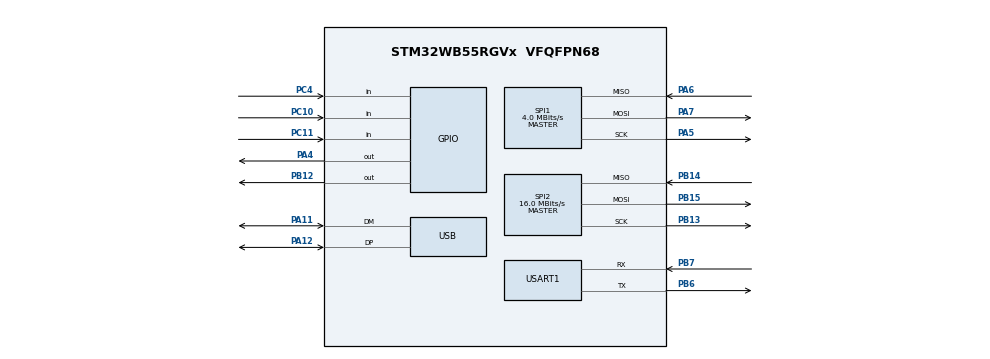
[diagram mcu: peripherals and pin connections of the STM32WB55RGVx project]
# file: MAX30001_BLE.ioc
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Dma.Request0=SPI1_RX
Dma.Request1=SPI1_TX
Dma.SPI1_RX.0.Direction=DMA_PERIPH_TO_MEMORY
Dma.SPI1_RX.0.EventEnable=DISABLE
Dma.SPI1_RX.0.Instance=DMA1_Channel1
Dma.SPI1_RX.0.MemDataAlignment=DMA_MDATAALIGN_BYTE
Dma.SPI1_RX.0.MemInc=DMA_MINC_ENABLE
Dma.SPI1_RX.0.Mode=DMA_NORMAL
Dma.SPI1_RX.0.PeriphDataAlignment=DMA_PDATAALIGN_BYTE
Dma.SPI1_RX.0.PeriphInc=DMA_PINC_DISABLE
Dma.SPI1_RX.0.Polarity=HAL_DMAMUX_REQ_GEN_RISING
Dma.SPI1_RX.0.Priority=DMA_PRIORITY_LOW
Dma.SPI1_RX.0.RequestNumber=1
Dma.SPI1_RX.0.SignalID=NONE
Dma.SPI1_RX.0.SyncEnable=DISABLE
Dma.SPI1_RX.0.SyncPolarity=HAL_DMAMUX_SYNC_NO_EVENT
Dma.SPI1_RX.0.SyncRequestNumber=1
Dma.SPI1_RX.0.SyncSignalID=NONE
Dma.SPI1_TX.1.Direction=DMA_MEMORY_TO_PERIPH
Dma.SPI1_TX.1.EventEnable=DISABLE
Dma.SPI1_TX.1.Instance=DMA1_Channel2
Dma.SPI1_TX.1.MemDataAlignment=DMA_MDATAALIGN_BYTE
Dma.SPI1_TX.1.MemInc=DMA_MINC_ENABLE
Dma.SPI1_TX.1.Mode=DMA_NORMAL
Dma.SPI1_TX.1.PeriphDataAlignment=DMA_PDATAALIGN_BYTE
Dma.SPI1_TX.1.PeriphInc=DMA_PINC_DISABLE
Dma.SPI1_TX.1.Polarity=HAL_DMAMUX_REQ_GEN_RISING
Dma.SPI1_TX.1.Priority=DMA_PRIORITY_LOW
Dma.SPI1_TX.1.RequestNumber=1
Dma.SPI1_TX.1.SignalID=NONE
Dma.SPI1_TX.1.SyncEnable=DISABLE
Dma.SPI1_TX.1.SyncPolarity=HAL_DMAMUX_SYNC_NO_EVENT
Dma.SPI1_TX.1.SyncRequestNumber=1
Dma.SPI1_TX.1.SyncSignalID=NONE
Mcu.Family=STM32WB
Mcu.Name=STM32WB55RGVx
Mcu.Package=VFQFPN68
NVIC.DMA1_Channel1_IRQn=true\:0\:0\:false\:false\:true\:false\:true
NVIC.DMA1_Channel2_IRQn=true\:0\:0\:false\:false\:true\:false\:true
NVIC.PriorityGroup=NVIC_PRIORITYGROUP_4
NVIC.USART1_IRQn=true\:0\:0\:false\:false\:true\:true\:true
NVIC.USB_LP_IRQn=true\:0\:0\:false\:false\:true\:true\:true
OSC_IN.Mode=HSE-External-Oscillator
OSC_IN.Signal=RCC_OSC_IN
OSC_OUT.Mode=HSE-External-Oscillator
OSC_OUT.Signal=RCC_OSC_OUT
PA11.Mode=Device
PA11.Signal=USB_DM
PA12.Mode=Device
PA12.Signal=USB_DP
PA13.Mode=Serial_Wire
PA13.Signal=SYS_JTMS-SWDIO
PA14.Mode=Serial_Wire
PA14.Signal=SYS_JTCK-SWCLK
PA4.GPIO_PuPd=GPIO_NOPULL
PA4.Signal=GPIO_Output
PA5.Mode=Full_Duplex_Master
PA5.Signal=SPI1_SCK
PA6.Mode=Full_Duplex_Master
PA6.Signal=SPI1_MISO
PA7.Mode=Full_Duplex_Master
PA7.Signal=SPI1_MOSI
PB12.GPIO_PuPd=GPIO_NOPULL
PB12.Signal=GPIO_Output
PB13.Mode=Full_Duplex_Master
PB13.Signal=SPI2_SCK
PB14.Mode=Full_Duplex_Master
PB14.Signal=SPI2_MISO
PB15.Mode=Full_Duplex_Master
PB15.Signal=SPI2_MOSI
PB6.GPIO_Speed=GPIO_SPEED_FREQ_VERY_HIGH
PB6.Mode=Asynchronous
PB6.Signal=USART1_TX
PB7.GPIO_PuPd=GPIO_PULLDOWN
PB7.GPIO_Speed=GPIO_SPEED_FREQ_VERY_HIGH
PB7.Mode=Asynchronous
PB7.Signal=USART1_RX
PC10.Signal=GPIO_Input
PC11.Signal=GPIO_Input
PC14-OSC32_IN.Mode=LSE-External-Oscillator
PC14-OSC32_IN.Signal=RCC_OSC32_IN
PC15-OSC32_OUT.Mode=LSE-External-Oscillator
PC15-OSC32_OUT.Signal=RCC_OSC32_OUT
PC4.Signal=GPIO_Input
ProjectManager.HeapSize=0x200
ProjectManager.StackSize=0x400
ProjectManager.TargetToolchain=STM32CubeIDE
RCC.ADCFreq_Value=128000000
RCC.AHBFreq_Value=32000000
RCC.APB1Freq_Value=32000000
RCC.APB1TimFreq_Value=32000000
RCC.APB2Freq_Value=32000000
RCC.APB2TimFreq_Value=32000000
RCC.APB3Freq_Value=16000000
RCC.CK48CLockSelection=RCC_USBCLKSOURCE_HSI48
RCC.CortexFreq_Value=32000000
RCC.HCLKFreq_Value=32000000
RCC.HSE_VALUE=32000000
RCC.HSI48_VALUE=48000000
RCC.HSI_VALUE=16000000
RCC.MSIClockRange=RCC_MSIRANGE_10
RCC.SYSCLKFreq_VALUE=32000000
RCC.USBFreq_Value=48000000
RCC.VCOOutputFreq_Value=256000000
RCC.VDD_VALUE=1.8
RF1.Mode=RF1_Activate
RF1.Signal=RF_RF1
RTC.AsynchPrediv=CFG_RTC_ASYNCH_PRESCALER
SPI1.BaudRatePrescaler=SPI_BAUDRATEPRESCALER_8
SPI1.CLKPhase=SPI_PHASE_2EDGE
SPI1.CLKPolarity=SPI_POLARITY_HIGH
SPI1.CalculateBaudRate=4.0 MBits/s
SPI1.DataSize=SPI_DATASIZE_8BIT
SPI1.Direction=SPI_DIRECTION_2LINES
SPI1.Mode=SPI_MODE_MASTER
SPI1.VirtualType=VM_MASTER
SPI2.CalculateBaudRate=16.0 MBits/s
SPI2.DataSize=SPI_DATASIZE_8BIT
SPI2.Direction=SPI_DIRECTION_2LINES
SPI2.Mode=SPI_MODE_MASTER
SPI2.NSSPMode=SPI_NSS_PULSE_DISABLE
SPI2.VirtualType=VM_MASTER
USART1.VirtualMode-Asynchronous=VM_ASYNC
USB_DEVICE.CLASS_NAME_FS=CDC
USB_DEVICE.VirtualMode=Cdc
USB_DEVICE.VirtualModeFS=Cdc_FS
VP_HSEM_VS_HSEM.Mode=HSEM_Activate
VP_RTC_VS_RTC_Activate.Mode=RTC_Enabled
VP_SEQUENCER_VS_SEQUENCER.Mode=SEQUENCER_Enabled
VP_STM32_WPAN_VS_BLE_HOST.Mode=STM32_WPAN_Enabled
VP_TINY_LPM_VS_TINY_LPM.Mode=TINY_LPM_Enabled
VP_USB_DEVICE_VS_USB_DEVICE_CDC_FS.Mode=CDC_FS
board=custom

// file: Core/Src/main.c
/* USER CODE BEGIN Header */
/**
  ******************************************************************************
  * @file           : main.c
  * @brief          : Main program body
  ******************************************************************************
  * @attention
  *
  * <h2><center>&copy; Copyright (c) 2020 STMicroelectronics.
  * All rights reserved.</center></h2>
  *
  * This software component is licensed by ST under BSD 3-Clause license,
  * the "License"; You may not use this file except in compliance with the
  * License. You may obtain a copy of the License at:
  *                        opensource.org/licenses/BSD-3-Clause
  *
  ******************************************************************************
  */
/* USER CODE END Header */

#include "main.h"
#include "app_entry.h"
#include "app_common.h"
#include "usb_device.h"

/* USER CODE BEGIN Includes */
#include <string.h>
#include <math.h>
#include "max30001.h"
#include "ICM20948.h"
#include "output_mode.h"
#include "BPM_calc.h"
#include "stm32_seq.h"
#include "otp.h"
/* USER CODE END Includes */

RTC_HandleTypeDef hrtc;
SPI_HandleTypeDef hspi1;
SPI_HandleTypeDef hspi2;
DMA_HandleTypeDef hdma_spi1_rx;
DMA_HandleTypeDef hdma_spi1_tx;
UART_HandleTypeDef huart1;

void SystemClock_Config(void);
static void MX_GPIO_Init(void);
static void MX_DMA_Init(void);
static void MX_RF_Init(void);
static void MX_RTC_Init(void);
static void MX_SPI1_Init(void);
static void MX_SPI2_Init(void);
static void MX_USART1_UART_Init(void);
static void Config_HSE(void); //dodano
/* USER CODE BEGIN PFP */
#ifdef __GNUC__
/* With GCC, small printf (option LD Linker->Libraries->Small printf
   set to 'Yes') calls __io_putchar() */
#define PUTCHAR_PROTOTYPE int __io_putchar(int ch)
#else
#define PUTCHAR_PROTOTYPE int fputc(int ch, FILE *f)
#endif /* __GNUC__ */
/* USER CODE END PFP */

/* globalne varijable*/
_Bool USB_new_command=0;  //ostatak od prije nego se koristio task sequencer, i dalje je u kodu, ali ne smeta
char USB_command[30]="";
char USB_parameter[6]="";
int output_mode = 0;  //sluzi za odabir nacina rada (moguce mijenjati preko USB-a)
uint32_t reg=0;       //hex vrijednost koju je potrebno upisati u registar (primljeno preko USB-a) -> koristi se u void usb_command(void)

int main(void)
{
  /* Reset of all peripherals, Initializes the Flash interface and the Systick. */
  HAL_Init();

  Config_HSE(); //dodano jer se nije spajao BLE

  /* Configure the system clock */
  SystemClock_Config();

  /* Initialize all configured peripherals */
  MX_GPIO_Init();
  MX_DMA_Init();
  MX_RF_Init();
  MX_RTC_Init();
  MX_SPI1_Init();
  MX_SPI2_Init();
  MX_USART1_UART_Init();
  MX_USB_Device_Init();

  //MAX30001 initialisation
  MAX30001_init();
  max30001_synch();

  //ICM-20948 initialisation
  ICM_SelectBank(USER_BANK_0);
  HAL_Delay(10);
  ICM_PowerOn();
  HAL_Delay(10);

  /* Init code for STM32_WPAN */
  APPE_Init();

  /* Infinite loop */

  while (1)
  {
	  UTIL_SEQ_Run( UTIL_SEQ_DEFAULT );
  }
}

void SystemClock_Config(void)
{
  RCC_OscInitTypeDef RCC_OscInitStruct = {0};
  RCC_ClkInitTypeDef RCC_ClkInitStruct = {0};
  RCC_PeriphCLKInitTypeDef PeriphClkInitStruct = {0};

  /** Configure LSE Drive Capability*/
    __HAL_RCC_LSEDRIVE_CONFIG(RCC_LSEDRIVE_LOW);

  /** Configure the main internal regulator output voltage
  */
  __HAL_PWR_VOLTAGESCALING_CONFIG(PWR_REGULATOR_VOLTAGE_SCALE1);

  /**********************************************************USB+BLE fix*****************
  /**
    * This prevents the CPU2 to disable the HSI48 oscillator when
    * it does not use anymore the RNG IP
    */
  LL_HSEM_1StepLock( HSEM, 5 );
  /**********************************************************USB+BLE fix*****************
  /** Initializes the CPU, AHB and APB busses clocks
  */
  RCC_OscInitStruct.OscillatorType = RCC_OSCILLATORTYPE_HSI48|RCC_OSCILLATORTYPE_HSI
                              |RCC_OSCILLATORTYPE_LSI1|RCC_OSCILLATORTYPE_HSE
                              |RCC_OSCILLATORTYPE_MSI|RCC_OSCILLATORTYPE_LSE;
  RCC_OscInitStruct.HSEState = RCC_HSE_ON;
  RCC_OscInitStruct.LSEState = RCC_LSE_ON;
  RCC_OscInitStruct.HSIState = RCC_HSI_ON;
  RCC_OscInitStruct.MSIState = RCC_MSI_ON;
  RCC_OscInitStruct.HSI48State = RCC_HSI48_ON;
  RCC_OscInitStruct.HSICalibrationValue = RCC_HSICALIBRATION_DEFAULT;
  RCC_OscInitStruct.MSICalibrationValue = RCC_MSICALIBRATION_DEFAULT;
  RCC_OscInitStruct.MSIClockRange = RCC_MSIRANGE_10;
  RCC_OscInitStruct.LSIState = RCC_LSI_ON;
  RCC_OscInitStruct.PLL.PLLState = RCC_PLL_NONE;
  if (HAL_RCC_OscConfig(&RCC_OscInitStruct) != HAL_OK)
  {
    Error_Handler();
  }
  /** Configure the SYSCLKSource, HCLK, PCLK1 and PCLK2 clocks dividers
  */
  RCC_ClkInitStruct.ClockType = RCC_CLOCKTYPE_HCLK4|RCC_CLOCKTYPE_HCLK2
                              |RCC_CLOCKTYPE_HCLK|RCC_CLOCKTYPE_SYSCLK
                              |RCC_CLOCKTYPE_PCLK1|RCC_CLOCKTYPE_PCLK2;
  RCC_ClkInitStruct.SYSCLKSource = RCC_SYSCLKSOURCE_MSI;
  RCC_ClkInitStruct.AHBCLKDivider = RCC_SYSCLK_DIV1;
  RCC_ClkInitStruct.APB1CLKDivider = RCC_HCLK_DIV1;
  RCC_ClkInitStruct.APB2CLKDivider = RCC_HCLK_DIV1;
  RCC_ClkInitStruct.AHBCLK2Divider = RCC_SYSCLK_DIV1;
  RCC_ClkInitStruct.AHBCLK4Divider = RCC_SYSCLK_DIV1;

  if (HAL_RCC_ClockConfig(&RCC_ClkInitStruct, FLASH_LATENCY_1) != HAL_OK)
  {
    Error_Handler();
  }
  /** Initializes the peripherals clocks
  */
  PeriphClkInitStruct.PeriphClockSelection = RCC_PERIPHCLK_SMPS|RCC_PERIPHCLK_RFWAKEUP
                              |RCC_PERIPHCLK_RTC|RCC_PERIPHCLK_USART1
                              |RCC_PERIPHCLK_USB;
  PeriphClkInitStruct.Usart1ClockSelection = RCC_USART1CLKSOURCE_PCLK2;
  PeriphClkInitStruct.UsbClockSelection = RCC_USBCLKSOURCE_HSI48;
  //PeriphClkInitStruct.RTCClockSelection = RCC_RTCCLKSOURCE_LSI;
  PeriphClkInitStruct.RTCClockSelection = RCC_RTCCLKSOURCE_LSE;
  //PeriphClkInitStruct.RFWakeUpClockSelection = RCC_RFWKPCLKSOURCE_LSI;
  PeriphClkInitStruct.RFWakeUpClockSelection = RCC_RFWKPCLKSOURCE_LSE;
  PeriphClkInitStruct.SmpsClockSelection = RCC_SMPSCLKSOURCE_HSE;
  PeriphClkInitStruct.SmpsDivSelection = RCC_SMPSCLKDIV_RANGE0;

  if (HAL_RCCEx_PeriphCLKConfig(&PeriphClkInitStruct) != HAL_OK)
  {
    Error_Handler();
  }
}

static void MX_RF_Init(void)
{

}

static void MX_RTC_Init(void)
{

  /** Initialize RTC Only
  */
  hrtc.Instance = RTC;
  hrtc.Init.HourFormat = RTC_HOURFORMAT_24;
  hrtc.Init.AsynchPrediv = CFG_RTC_ASYNCH_PRESCALER;
  hrtc.Init.SynchPrediv = CFG_RTC_SYNCH_PRESCALER;
  hrtc.Init.OutPut = RTC_OUTPUT_DISABLE;
  hrtc.Init.OutPutPolarity = RTC_OUTPUT_POLARITY_HIGH;
  hrtc.Init.OutPutType = RTC_OUTPUT_TYPE_OPENDRAIN;
  if (HAL_RTC_Init(&hrtc) != HAL_OK)
  {
    Error_Handler();
  }
  /* USER CODE BEGIN RTC_Init 2 */
  /* Disable RTC registers write protection */
  LL_RTC_DisableWriteProtection(RTC);

  LL_RTC_WAKEUP_SetClock(RTC, CFG_RTC_WUCKSEL_DIVIDER);

  /* Enable RTC registers write protection */
  LL_RTC_EnableWriteProtection(RTC);
  /* USER CODE END RTC_Init 2 */

}

static void MX_SPI1_Init(void)
{

  /* SPI1 parameter configuration*/
  hspi1.Instance = SPI1;
  hspi1.Init.Mode = SPI_MODE_MASTER;
  hspi1.Init.Direction = SPI_DIRECTION_2LINES;
  hspi1.Init.DataSize = SPI_DATASIZE_8BIT;
  hspi1.Init.CLKPolarity = SPI_POLARITY_HIGH;
  hspi1.Init.CLKPhase = SPI_PHASE_2EDGE;
  hspi1.Init.NSS = SPI_NSS_SOFT;
  hspi1.Init.BaudRatePrescaler = SPI_BAUDRATEPRESCALER_256; //bio je 8, ali stavio sam 256 da mogu debuggirat na svojem osciloskopu
  hspi1.Init.FirstBit = SPI_FIRSTBIT_MSB;
  hspi1.Init.TIMode = SPI_TIMODE_DISABLE;
  hspi1.Init.CRCCalculation = SPI_CRCCALCULATION_DISABLE;
  hspi1.Init.CRCPolynomial = 7;
  hspi1.Init.CRCLength = SPI_CRC_LENGTH_DATASIZE;
  hspi1.Init.NSSPMode = SPI_NSS_PULSE_DISABLE;
  if (HAL_SPI_Init(&hspi1) != HAL_OK)
  {
    Error_Handler();
  }

}

static void MX_SPI2_Init(void)
{

  /* SPI2 parameter configuration*/
  hspi2.Instance = SPI2;
  hspi2.Init.Mode = SPI_MODE_MASTER;
  hspi2.Init.Direction = SPI_DIRECTION_2LINES;
  hspi2.Init.DataSize = SPI_DATASIZE_8BIT;
  hspi2.Init.CLKPolarity = SPI_POLARITY_LOW;
  hspi2.Init.CLKPhase = SPI_PHASE_1EDGE;
  hspi2.Init.NSS = SPI_NSS_SOFT;
  hspi2.Init.BaudRatePrescaler = SPI_BAUDRATEPRESCALER_256; //bio je 8, ali stavio sam 256 da mogu debuggirat na svojem osciloskopu
  hspi2.Init.FirstBit = SPI_FIRSTBIT_MSB;
  hspi2.Init.TIMode = SPI_TIMODE_DISABLE;
  hspi2.Init.CRCCalculation = SPI_CRCCALCULATION_DISABLE;
  hspi2.Init.CRCPolynomial = 7;
  hspi2.Init.CRCLength = SPI_CRC_LENGTH_DATASIZE;
  hspi2.Init.NSSPMode = SPI_NSS_PULSE_DISABLE;
  if (HAL_SPI_Init(&hspi2) != HAL_OK)
  {
    Error_Handler();
  }

}

static void MX_USART1_UART_Init(void)
{

  huart1.Instance = USART1;
  huart1.Init.BaudRate = 115200;
  huart1.Init.WordLength = UART_WORDLENGTH_8B;
  huart1.Init.StopBits = UART_STOPBITS_1;
  huart1.Init.Parity = UART_PARITY_NONE;
  huart1.Init.Mode = UART_MODE_TX_RX;
  huart1.Init.HwFlowCtl = UART_HWCONTROL_NONE;
  huart1.Init.OverSampling = UART_OVERSAMPLING_16;
  huart1.Init.OneBitSampling = UART_ONE_BIT_SAMPLE_DISABLE;
  huart1.Init.ClockPrescaler = UART_PRESCALER_DIV1;
  huart1.AdvancedInit.AdvFeatureInit = UART_ADVFEATURE_NO_INIT;
  if (HAL_UART_Init(&huart1) != HAL_OK)
  {
    Error_Handler();
  }
  if (HAL_UARTEx_SetTxFifoThreshold(&huart1, UART_TXFIFO_THRESHOLD_1_8) != HAL_OK)
  {
    Error_Handler();
  }
  if (HAL_UARTEx_SetRxFifoThreshold(&huart1, UART_RXFIFO_THRESHOLD_1_8) != HAL_OK)
  {
    Error_Handler();
  }
  if (HAL_UARTEx_DisableFifoMode(&huart1) != HAL_OK)
  {
    Error_Handler();
  }

}

static void MX_DMA_Init(void)
{

  /* DMA controller clock enable */
  __HAL_RCC_DMAMUX1_CLK_ENABLE();
  __HAL_RCC_DMA1_CLK_ENABLE();

  /* DMA interrupt init */
  /* DMA1_Channel1_IRQn interrupt configuration */
  HAL_NVIC_SetPriority(DMA1_Channel1_IRQn, 0, 0);
  HAL_NVIC_EnableIRQ(DMA1_Channel1_IRQn);
  /* DMA1_Channel2_IRQn interrupt configuration */
  HAL_NVIC_SetPriority(DMA1_Channel2_IRQn, 0, 0);
  HAL_NVIC_EnableIRQ(DMA1_Channel2_IRQn);

}

static void MX_GPIO_Init(void)
{
  GPIO_InitTypeDef GPIO_InitStruct = {0};

  /* GPIO Ports Clock Enable */
  __HAL_RCC_GPIOC_CLK_ENABLE();
  __HAL_RCC_GPIOA_CLK_ENABLE();
  __HAL_RCC_GPIOB_CLK_ENABLE();

  /*Configure GPIO pin Output Level */
  HAL_GPIO_WritePin(GPIOA, GPIO_PIN_4, GPIO_PIN_RESET);

  /*Configure GPIO pin Output Level */
  HAL_GPIO_WritePin(GPIOB, GPIO_PIN_12, GPIO_PIN_RESET);

  /*Configure GPIO pin : PA4 (NSS_SPI1_Pin)*/
  GPIO_InitStruct.Pin = GPIO_PIN_4;
  GPIO_InitStruct.Mode = GPIO_MODE_OUTPUT_PP;
  GPIO_InitStruct.Pull = GPIO_NOPULL;
  GPIO_InitStruct.Speed = GPIO_SPEED_FREQ_LOW;
  HAL_GPIO_Init(GPIOA, &GPIO_InitStruct);

  /*Configure GPIO pins : PC4 (INT_ICM) PC10 (INT2B) PC11 (INTB) */
  GPIO_InitStruct.Pin = GPIO_PIN_4|GPIO_PIN_10|GPIO_PIN_11;
  GPIO_InitStruct.Mode = GPIO_MODE_IT_FALLING;
  GPIO_InitStruct.Pull = GPIO_PULLUP;
  HAL_GPIO_Init(GPIOC, &GPIO_InitStruct);

  /*Configure GPIO pin : PB12  (NSS_SPI2_Pin)*/
  GPIO_InitStruct.Pin = GPIO_PIN_12;
  GPIO_InitStruct.Mode = GPIO_MODE_OUTPUT_PP;
  GPIO_InitStruct.Pull = GPIO_NOPULL;
  GPIO_InitStruct.Speed = GPIO_SPEED_FREQ_LOW;
  HAL_GPIO_Init(GPIOB, &GPIO_InitStruct);

  /*Configure GPIO pin : PB0 (Green LED) */
  GPIO_InitStruct.Pin = GPIO_PIN_0;
  GPIO_InitStruct.Mode = GPIO_MODE_OUTPUT_PP;
  GPIO_InitStruct.Pull = GPIO_NOPULL;
  GPIO_InitStruct.Speed = GPIO_SPEED_FREQ_LOW;
  HAL_GPIO_Init(GPIOB, &GPIO_InitStruct);

  /*configure interrupts*/
  HAL_NVIC_SetPriority(EXTI15_10_IRQn, 0, 0);  //INTB and INT2B
  HAL_NVIC_SetPriority(EXTI4_IRQn, 0, 0);      //INT_ICM
//  HAL_NVIC_EnableIRQ(EXTI15_10_IRQn);
//  HAL_NVIC_EnableIRQ(EXTI4_IRQn);
}

/**
  * @brief EXTI line detection callbacks
  * @param GPIO_Pin: Specifies the pins connected EXTI line
  * @retval None
  */
void HAL_GPIO_EXTI_Callback(uint16_t GPIO_Pin)
{
  if (GPIO_Pin == INTB_Pin)
  {
	  if (output_mode == ECG_OUTPUT_MODE)
	  {
		  /* Set ECG OUTPUT MODE task */
		  printf("postavljam ecg output mode task\r\n");
		  UTIL_SEQ_SetTask( 1<<CFG_TASK_ECG_OUTPUT_MODE, CFG_SCH_PRIO_0);
	  }
	  if (output_mode == RTOR_OUTPUT_MODE)
	  {
		  /* Set RTOR OUTPUT MODE task */
		  printf("postavljam rtor output mode task\r\n");
		  UTIL_SEQ_SetTask( 1<<CFG_TASK_RTOR_OUTPUT_MODE, CFG_SCH_PRIO_0);
	  }
	  if (output_mode == HR_ECG_OUTPUT_MODE)
	  {
		  /* Set RTOR OUTPUT MODE task */
		  printf("postavljam rtor&ECG output mode task\r\n");
		  UTIL_SEQ_SetTask( 1<<CFG_TASK_HR_ECG_OUTPUT_MODE, CFG_SCH_PRIO_0);
	  }
  }
  else if (GPIO_Pin == INT2B_Pin)
  {
	  if (output_mode == BIOZ_OUTPUT_MODE)
	  {
		  /* Set BIOZ OUTPUT MODE task*/
		  printf("postavljam bioz output mode task\r\n");
		  UTIL_SEQ_SetTask( 1<<CFG_TASK_BIOZ_OUTPUT_MODE, CFG_SCH_PRIO_0);
	  }
	  if (output_mode == BPM_OUTPUT_MODE)
	  {
		  /* Set BIOZ OUTPUT MODE task*/
		  printf("postavljam bpm output mode task\r\n");
		  UTIL_SEQ_SetTask( 1<<CFG_TASK_BPM_OUTPUT_MODE, CFG_SCH_PRIO_0);
	  }
	  if (output_mode == BPM60_BIOZ_OUTPUT_MODE)
	  {
		  /* Set BPM60&BIOZ OUTPUT MODE task*/
		  printf("postavljam bpm60_bioz output mode task\r\n");
		  UTIL_SEQ_SetTask( 1<<CFG_TASK_BPM60_BIOZ_OUTPUT_MODE, CFG_SCH_PRIO_0);
	  }
	  if (output_mode == BPM30_BIOZ_OUTPUT_MODE)
	  {
		  /* Set BPM30&BIOZ OUTPUT MODE task*/
		  printf("postavljam bpm30_bioz output mode task\r\n");
		  UTIL_SEQ_SetTask( 1<<CFG_TASK_BPM30_BIOZ_OUTPUT_MODE, CFG_SCH_PRIO_0);
	  }
  }
  else if (GPIO_Pin == INT_ICM_Pin)
  {
	  if (output_mode == ACCEL_OUTPUT_MODE)
	  {
		  /* Set ACCEL OUTPUT MODE task*/
		  printf("postavljam accel output mode task\r\n");
		  UTIL_SEQ_SetTask( 1<<CFG_TASK_ACCEL_OUTPUT_MODE, CFG_SCH_PRIO_0);
	  }
	  if (output_mode == GYRO_OUTPUT_MODE)
	  {
		  /* Set GYRO OUTPUT MODE task*/
		  printf("postavljam gyro output mode task\r\n");
		  UTIL_SEQ_SetTask( 1<<CFG_TASK_GYRO_OUTPUT_MODE, CFG_SCH_PRIO_0);
	  }
	  if (output_mode == MAGN_OUTPUT_MODE)
	  {
		  /* Set MAGN OUTPUT MODE task*/
		  printf("postavljam magn output mode task\r\n");
		  UTIL_SEQ_SetTask( 1<<CFG_TASK_MAGN_OUTPUT_MODE, CFG_SCH_PRIO_0);
	  }
	  if (output_mode == TEMP_OUTPUT_MODE)
	  {
		  /* Set TEMP OUTPUT MODE task*/
		  printf("postavljam temp output mode task\r\n");
		  UTIL_SEQ_SetTask( 1<<CFG_TASK_TEMP_OUTPUT_MODE, CFG_SCH_PRIO_0);
	  }
	  if (output_mode == COMBINED_OUTPUT_MODE)
	  {
		  /* Set COMBINED OUTPUT MODE task*/
		  printf("postavljam combined output mode task\r\n");
		  UTIL_SEQ_SetTask( 1<<CFG_TASK_COMBINED_OUTPUT_MODE, CFG_SCH_PRIO_0);
	  }
  }
}
/* USER CODE BEGIN 4 */
/*
  * @brief  Retargets the C library printf function to the USART.
  * @param  None
  * @retval None
  */
PUTCHAR_PROTOTYPE
{
  /* Place your implementation of fputc here */
  /* e.g. write a character to the USART1 and Loop until the end of transmission */
  HAL_UART_Transmit(&huart1, (uint8_t *)&ch, 1, 0xFFFF);

  return ch;
}
/* USER CODE END 4 */

void Error_Handler(void)
{
}

static void Config_HSE(void)
{
    OTP_ID0_t * p_otp;

  /**
   * Read HSE_Tuning from OTP
   */
  p_otp = (OTP_ID0_t *) OTP_Read(0);
  if (p_otp)
  {
    LL_RCC_HSE_SetCapacitorTuning(p_otp->hse_tuning);
  }

  return;
}

void usb_command(void){
char buffer[100]="";
if(USB_new_command)
{
	if (strncmp(USB_command, "MAX", 3) == 0)
	max30001_usb_init(USB_command, reg);
	else if (strncmp(USB_command, "ICM", 3) == 0)
	icm_usb_init(USB_command, reg);
	else if (strncmp(USB_command, "MODE", 4) == 0)
	output_mode = change_output_mode(USB_command);
	else
	{
		sprintf(buffer, "Wrong USB command\r\n");
		CDC_Transmit_FS((uint8_t *)buffer, strlen(buffer)); //ispis poruke na USB VCOM port
	}
	USB_new_command=0;
 }
}

/************************ (C) COPYRIGHT STMicroelectronics *****END OF FILE****/
